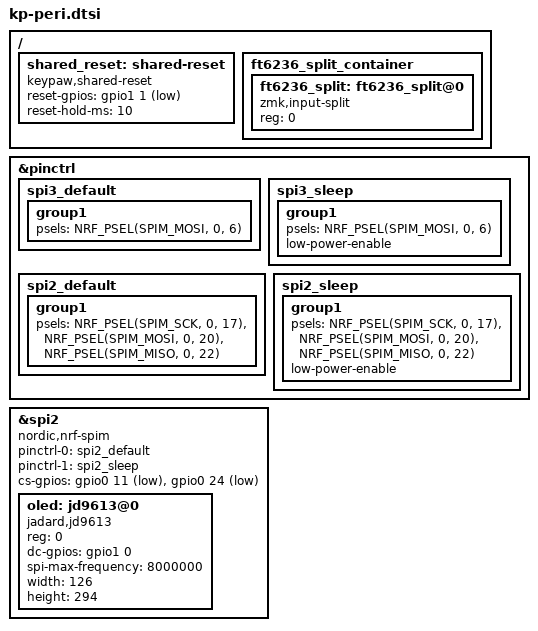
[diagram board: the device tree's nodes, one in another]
/*
 * Copyright (c) 2026 The ZMK Contributors
 * SPDX-License-Identifier: MIT
 */

/ {
    shared_reset: shared-reset {
        compatible = "keypaw,shared-reset";
        reset-gpios = <&gpio1 1 GPIO_ACTIVE_LOW>;
        reset-hold-ms = <10>;
    };

    ft6236_split_container: ft6236_split_container {
        #address-cells = <1>;
        #size-cells = <0>;

        ft6236_split: ft6236_split@0 {
            compatible = "zmk,input-split";
            reg = <0>;
        };
    };
};

&pinctrl {
    spi3_default: spi3_default {
        group1 {
            psels = <NRF_PSEL(SPIM_MOSI, 0, 6)>;
        };
    };

    spi3_sleep: spi3_sleep {
        group1 {
            psels = <NRF_PSEL(SPIM_MOSI, 0, 6)>;
            low-power-enable;
        };
    };

    spi2_default: spi2_default {
        group1 {
            psels = <NRF_PSEL(SPIM_SCK, 0, 17)>, <NRF_PSEL(SPIM_MOSI, 0, 20)>, <NRF_PSEL(SPIM_MISO, 0, 22)>;
        };
    };

    spi2_sleep: spi2_sleep {
        group1 {
            psels = <NRF_PSEL(SPIM_SCK, 0, 17)>, <NRF_PSEL(SPIM_MOSI, 0, 20)>, <NRF_PSEL(SPIM_MISO, 0, 22)>;
            low-power-enable;
        };
    };
};

&spi2 {
    compatible = "nordic,nrf-spim";
    status = "okay";

    pinctrl-0 = <&spi2_default>;
    pinctrl-1 = <&spi2_sleep>;
    pinctrl-names = "default", "sleep";
    cs-gpios = <&gpio0 11 GPIO_ACTIVE_LOW>, <&gpio0 24 GPIO_ACTIVE_LOW>;

    oled: jd9613@0 {
        compatible = "jadard,jd9613";

        reg = <0>;
        dc-gpios = <&gpio1 0 GPIO_ACTIVE_HIGH>;
        spi-max-frequency = <8000000>;

        width = <126>;
        height = <294>;
    };
};
